AUTOSAR XML (schema 00048)
package /HuaweiMDC/FunctionalSoftware/VisualSlam/Execution
  executable VisualSlamExecutable
    root sw component prototype VisualSlamSwComponent: application-type=VisualSlamApplicationSwComponent
package /HuaweiMDC/FunctionalSoftware/VisualSlam/SwComponent
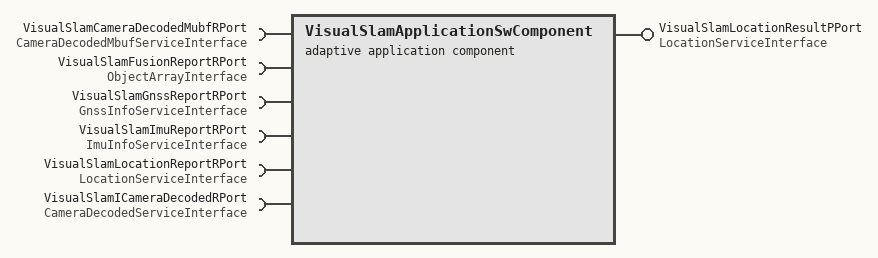
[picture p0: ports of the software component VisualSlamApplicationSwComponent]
  adaptive application sw component type VisualSlamApplicationSwComponent
    5 x require port:
      VisualSlamCameraDecodedMubfRPort: required-interface=CameraDecodedMbufServiceInterface
      VisualSlamFusionReportRPort: required-interface=ObjectArrayInterface
      VisualSlamGnssReportRPort: required-interface=GnssInfoServiceInterface
      VisualSlamImuReportRPort: required-interface=ImuInfoServiceInterface
      VisualSlamLocationReportRPort: required-interface=LocationServiceInterface
    provide port VisualSlamLocationResultPPort: provided-interface=LocationServiceInterface
    require port VisualSlamICameraDecodedRPort: required-interface=CameraDecodedServiceInterface
